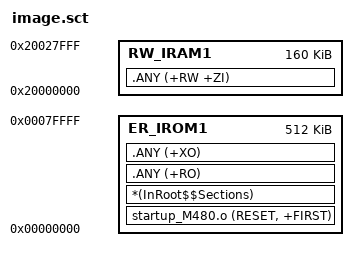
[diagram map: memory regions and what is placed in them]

; load region size_region
LR_IROM1 0x0 0x80000  
{ 
	ER_IROM1 0x0 0x80000  
	{
		startup_M480.o (RESET, +FIRST)
		*(InRoot$$Sections)
		.ANY (+RO)
		.ANY (+XO)
	}
	RW_IRAM1 0x20000000 0x28000  
	{
		.ANY (+RW +ZI)
	}
}
